AUTOSAR XML (schema 4-0-3)
package /ComponentTypes
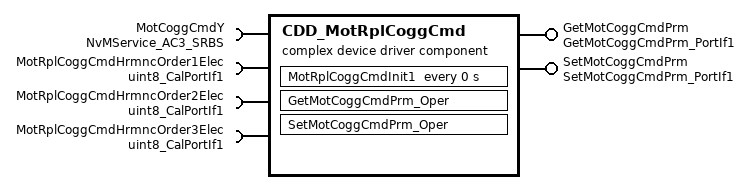
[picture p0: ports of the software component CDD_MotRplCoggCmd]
  complex device driver sw component type CDD_MotRplCoggCmd
    provide port GetMotCoggCmdPrm: server-com-spec{operation=Oper, queue-length=1}, provided-interface=GetMotCoggCmdPrm_PortIf1
    provide port SetMotCoggCmdPrm: server-com-spec{operation=Oper, queue-length=1}, provided-interface=SetMotCoggCmdPrm_PortIf1
    4 x require port:
      MotCoggCmdY: required-com-specs=[EraseBlock, GetErrorStatus, InvalidateNvBlock, ReadBlock, SetRamBlockStatus, WriteBlock], required-interface=NvMService_AC3_SRBS
      MotRplCoggCmdHrmncOrder1Elec: parameter-require-com-spec{init-value=6, parameter=Val}, required-interface=uint8_CalPortIf1
      MotRplCoggCmdHrmncOrder2Elec: parameter-require-com-spec{init-value=12, parameter=Val}, required-interface=uint8_CalPortIf1
      MotRplCoggCmdHrmncOrder3Elec: parameter-require-com-spec{init-value=18, parameter=Val}, required-interface=uint8_CalPortIf1
    behavior CDD_MotRplCoggCmd_InternalBehavior
      ar-typed-per-instance-memorys:
        5 x data, all with sw-calibration-access=READ-ONLY:
          dMotRplCoggCmdCoggIdx: type=uint16
          dMotRplCoggCmdMotCoggCmd: type=float32
          dMotRplCoggCmdMotCurrQaxCoggCmdPreLim: type=float32
          dMotRplCoggCmdMotRplCmdPreLim: type=float32
          MotCoggCmdY: type=Ary1D_s1p14_512
      operation invoked event OIT_GetMotCoggCmdPrm_Oper_GetMotCoggCmdPrm_Oper: start-on-event=GetMotCoggCmdPrm_Oper, operation=GetMotCoggCmdPrm.Oper
      timing event CDD_MotRplCoggCmd_InitEvent: start-on-event=MotRplCoggCmdInit1, period=0
      operation invoked event OIT_SetMotCoggCmdPrm_Oper_SetMotCoggCmdPrm_Oper: start-on-event=SetMotCoggCmdPrm_Oper, operation=SetMotCoggCmdPrm.Oper
      runnable GetMotCoggCmdPrm_Oper
      runnable MotRplCoggCmdInit1
        sync call SC_MotCoggCmdY_GetErrorStatus: operation=MotCoggCmdY.GetErrorStatus, timeout=0
        sync call SC_MotCoggCmdY_SetRamBlockStatus: operation=MotCoggCmdY.SetRamBlockStatus, timeout=0
      runnable SetMotCoggCmdPrm_Oper
        sync call SC_MotCoggCmdY_SetRamBlockStatus: operation=MotCoggCmdY.SetRamBlockStatus, timeout=0
      swc service dependency NvmMotCoggCmdY: assigned-datas=role-based-data-assignment={role=ramBlock, used-data-element=MotCoggCmdY}, assigned-ports=role-based-port-assignment={port-prototype=MotCoggCmdY, role=NvMService_AC3_SRBS}
        service-needs:
          nv block needs NvmMotCoggCmdY: n-data-sets=0, readonly=false, reliability=ERROR-DETECTION, resistant-to-changed-sw=true, restore-at-start=true, store-at-shutdown=true, write-only-once=false, writing-frequency=0, writing-priority=LOW
  swc implementation CDD_MotRplCoggCmd_Implementation: behavior=CDD_MotRplCoggCmd_InternalBehavior
    code-descriptors:
      code Default: artifact-descriptors=autosar-engineering-object={short-label=Default, category=SWSRC}
